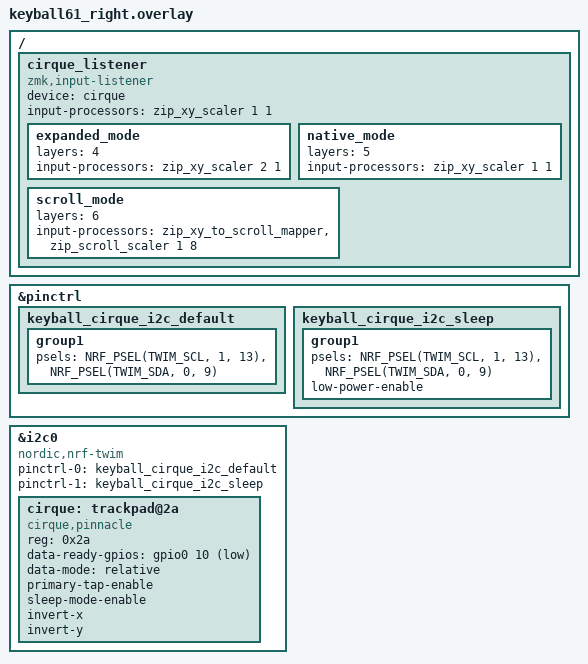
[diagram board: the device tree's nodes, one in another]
/*
 * Keyball61 right half + Cirque TM040040 / Rev M2 adapter.
 * SPDX-License-Identifier: MIT
 */

#include "keyball61_right_common.dtsi"
#include <zephyr/dt-bindings/pinctrl/nrf-pinctrl.h>
#include <input/processors.dtsi>

&pinctrl {
    keyball_cirque_i2c_default: keyball_cirque_i2c_default {
        group1 {
            psels = <NRF_PSEL(TWIM_SCL, 1, 13)>,
                    <NRF_PSEL(TWIM_SDA, 0, 9)>;
        };
    };

    keyball_cirque_i2c_sleep: keyball_cirque_i2c_sleep {
        group1 {
            psels = <NRF_PSEL(TWIM_SCL, 1, 13)>,
                    <NRF_PSEL(TWIM_SDA, 0, 9)>;
            low-power-enable;
        };
    };
};

&i2c0 {
    compatible = "nordic,nrf-twim";
    status = "okay";
    pinctrl-0 = <&keyball_cirque_i2c_default>;
    pinctrl-1 = <&keyball_cirque_i2c_sleep>;
    pinctrl-names = "default", "sleep";

    cirque: trackpad@2a {
        compatible = "cirque,pinnacle";
        reg = <0x2a>;
        status = "okay";
        data-ready-gpios = <&gpio0 10 GPIO_ACTIVE_LOW>;
        data-mode = "relative";
        primary-tap-enable;
        sleep-mode-enable;
        invert-x;
        invert-y;
    };
};

/ {
    cirque_listener: cirque_listener {
        compatible = "zmk,input-listener";
        device = <&cirque>;
        input-processors = <&zip_xy_scaler 1 1>;

        expanded_mode {
            layers = <4>;
            input-processors = <&zip_xy_scaler 2 1>;
        };

        native_mode {
            layers = <5>;
            input-processors = <&zip_xy_scaler 1 1>;
        };

        scroll_mode {
            layers = <6>;
            input-processors = <&zip_xy_to_scroll_mapper &zip_scroll_scaler 1 8>;
        };
    };
};
